AUTOSAR XML (schema 4-2-2)
package /ComponentTypes
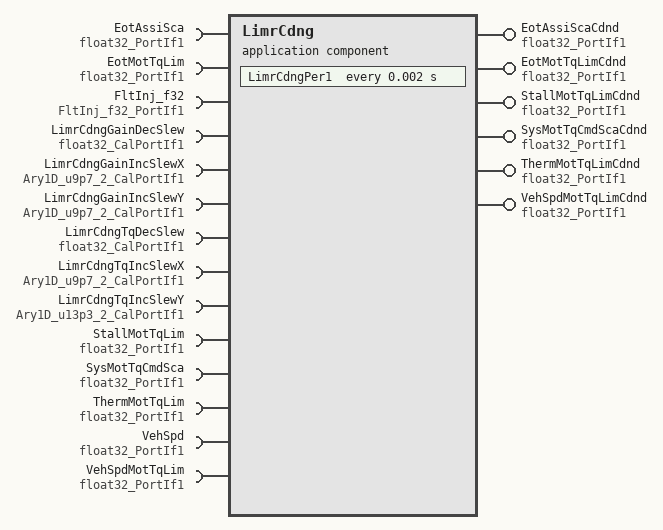
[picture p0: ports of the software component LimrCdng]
  application sw component type LimrCdng
    6 x provide port, all with provided-interface=float32_PortIf1:
      EotAssiScaCdnd: nonqueued-sender-com-spec{data-element=Val, init-value=1}
      EotMotTqLimCdnd: nonqueued-sender-com-spec{data-element=Val, init-value=8.8}
      StallMotTqLimCdnd: nonqueued-sender-com-spec{data-element=Val, init-value=8.8}
      SysMotTqCmdScaCdnd: nonqueued-sender-com-spec{data-element=Val, init-value=1}
      ThermMotTqLimCdnd: nonqueued-sender-com-spec{data-element=Val, init-value=8.8}
      VehSpdMotTqLimCdnd: nonqueued-sender-com-spec{data-element=Val, init-value=8.8}
    14 x require port:
      EotAssiSca: nonqueued-receiver-com-spec{data-element=Val, filter=data-filter-type=ALWAYS, init-value=1}, required-interface=float32_PortIf1
      EotMotTqLim: nonqueued-receiver-com-spec{data-element=Val, filter=data-filter-type=ALWAYS, init-value=8.8}, required-interface=float32_PortIf1
      FltInj_f32: client-com-spec=Oper, required-interface=FltInj_f32_PortIf1
      LimrCdngGainDecSlew: parameter-require-com-spec{init-value=500, parameter=Val}, required-interface=float32_CalPortIf1
      LimrCdngGainIncSlewX: parameter-require-com-spec{init-value=[1280, 2560], parameter=Ary1D}, required-interface=Ary1D_u9p7_2_CalPortIf1
      LimrCdngGainIncSlewY: parameter-require-com-spec{init-value=[64000, 64000], parameter=Ary1D}, required-interface=Ary1D_u9p7_2_CalPortIf1
      LimrCdngTqDecSlew: parameter-require-com-spec{init-value=4400, parameter=Val}, required-interface=float32_CalPortIf1
      LimrCdngTqIncSlewX: parameter-require-com-spec{init-value=[1280, 2560], parameter=Ary1D}, required-interface=Ary1D_u9p7_2_CalPortIf1
      LimrCdngTqIncSlewY: parameter-require-com-spec{init-value=[32500, 32500], parameter=Ary1D}, required-interface=Ary1D_u13p3_2_CalPortIf1
      StallMotTqLim: nonqueued-receiver-com-spec{data-element=Val, filter=data-filter-type=ALWAYS, init-value=8.8}, required-interface=float32_PortIf1
      SysMotTqCmdSca: nonqueued-receiver-com-spec{data-element=Val, filter=data-filter-type=ALWAYS, init-value=1}, required-interface=float32_PortIf1
      ThermMotTqLim: nonqueued-receiver-com-spec{data-element=Val, filter=data-filter-type=ALWAYS, init-value=8.8}, required-interface=float32_PortIf1
      VehSpd: nonqueued-receiver-com-spec{data-element=Val, filter=data-filter-type=ALWAYS, init-value=0}, required-interface=float32_PortIf1
      VehSpdMotTqLim: nonqueued-receiver-com-spec{data-element=Val, filter=data-filter-type=ALWAYS, init-value=8.8}, required-interface=float32_PortIf1
    behavior LimrCdng_InternalBehavior
      ar-typed-per-instance-memorys:
        6 x data, all with sw-calibration-access=READ-ONLY, type=float32:
          PrevEotAssiScaCdnd
          PrevEotMotTqLimCdnd
          PrevStallMotTqLimCdnd
          PrevSysMotTqCmdScaCdnd
          PrevThermMotTqLimCdnd
          PrevVehSpdMotTqLimCdnd
      timing event TMT_LimrCdngPer1: start-on-event=LimrCdngPer1, period=0.002
      runnable LimrCdngPer1
        data-receive-point-by-arguments:
          7 x access:
            REC_EotAssiSca_Val: accessed-variable=EotAssiSca.Val
            REC_EotMotTqLim_Val: accessed-variable=EotMotTqLim.Val
            REC_StallMotTqLim_Val: accessed-variable=StallMotTqLim.Val
            REC_SysMotTqCmdSca_Val: accessed-variable=SysMotTqCmdSca.Val
            REC_ThermMotTqLim_Val: accessed-variable=ThermMotTqLim.Val
            REC_VehSpd_Val: accessed-variable=VehSpd.Val
            REC_VehSpdMotTqLim_Val: accessed-variable=VehSpdMotTqLim.Val
        data-send-points:
          6 x access:
            SEND_EotAssiScaCdnd_Val: accessed-variable=EotAssiScaCdnd.Val
            SEND_EotMotTqLimCdnd_Val: accessed-variable=EotMotTqLimCdnd.Val
            SEND_StallMotTqLimCdnd_Val: accessed-variable=StallMotTqLimCdnd.Val
            SEND_SysMotTqCmdScaCdnd_Val: accessed-variable=SysMotTqCmdScaCdnd.Val
            SEND_ThermMotTqLimCdnd_Val: accessed-variable=ThermMotTqLimCdnd.Val
            SEND_VehSpdMotTqLimCdnd_Val: accessed-variable=VehSpdMotTqLimCdnd.Val
        sync call SC_FltInj_f32_Oper: operation=FltInj_f32.Oper, timeout=0
  swc implementation LimrCdng_Implementation: behavior=LimrCdng_InternalBehavior
    code-descriptors:
      code Default: artifact-descriptors=autosar-engineering-object={short-label=Default, category=SWSRC}
